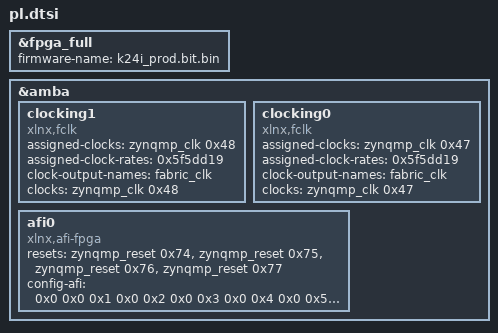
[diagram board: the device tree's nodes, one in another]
/dts-v1/;
/plugin/;
&fpga_full{
	firmware-name = "k24i_prod.bit.bin";
};
&amba{
	clocking1: clocking1 {
		compatible = "xlnx,fclk";
		status = "okay";
		assigned-clocks = <&zynqmp_clk 0x48>;
		assigned-clock-rates = <0x5f5dd19>;
		#clock-cells = <0x0>;
		clock-output-names = "fabric_clk";
		clocks = <&zynqmp_clk 0x48>;
	};
	clocking0: clocking0 {
		compatible = "xlnx,fclk";
		status = "okay";
		assigned-clocks = <&zynqmp_clk 0x47>;
		assigned-clock-rates = <0x5f5dd19>;
		#clock-cells = <0x0>;
		clock-output-names = "fabric_clk";
		clocks = <&zynqmp_clk 0x47>;
	};
	afi0: afi0 {
		status = "okay";
		compatible = "xlnx,afi-fpga";
		resets = <&zynqmp_reset 0x74>,
<&zynqmp_reset 0x75>,
<&zynqmp_reset 0x76>,
<&zynqmp_reset 0x77>;
		config-afi = <0x0 0x0 0x1 0x0 0x2 0x0 0x3 0x0 0x4 0x0 0x5 0x0 0x6 0x0 0x7 0x0 0x8 0x0 0x9 0x0 0xa 0x0 0xb 0x0 0xc 0x0 0xd 0x0 0xe 0xa00 0xf 0x0>;
	};
};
